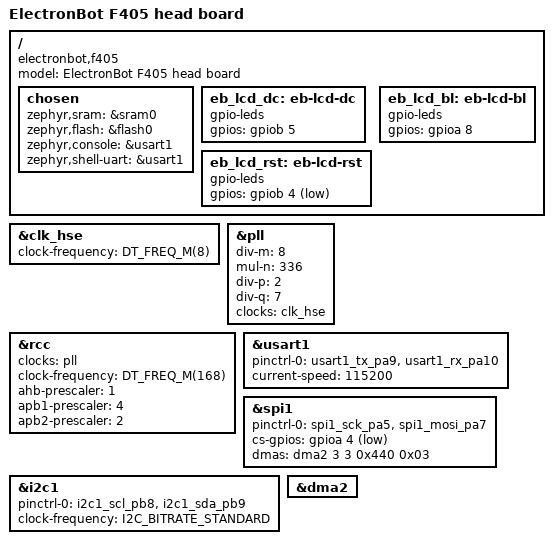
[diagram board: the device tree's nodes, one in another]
/*
 * ElectronBot head board - STM32F405RGT6.
 *
 * Pin assignments below follow the original design (SPI1 for the GC9A01 LCD,
 * I2C1 SCL=PB8 / SDA=PB9 for the servo bus). CONFIRM against 1.Hardware before
 * relying on them - marked with TODO where the schematic is the source of truth.
 */
/dts-v1/;
#include <st/f4/stm32f405Xg.dtsi>
#include <st/f4/stm32f405rgtx-pinctrl.dtsi>
#include <zephyr/dt-bindings/gpio/gpio.h>

/ {
	model = "ElectronBot F405 head board";
	compatible = "electronbot,f405";

	chosen {
		zephyr,sram = &sram0;
		zephyr,flash = &flash0;
		zephyr,console = &usart1;
		zephyr,shell-uart = &usart1;
	};

	/* LCD control GPIOs (DC / RST / backlight). TODO: confirm pins. */
	eb_lcd_dc: eb-lcd-dc {
		compatible = "gpio-leds";
		gpios = <&gpiob 5 GPIO_ACTIVE_HIGH>;
	};
	eb_lcd_rst: eb-lcd-rst {
		compatible = "gpio-leds";
		gpios = <&gpiob 4 GPIO_ACTIVE_LOW>;
	};
	eb_lcd_bl: eb-lcd-bl {
		compatible = "gpio-leds";
		gpios = <&gpioa 8 GPIO_ACTIVE_HIGH>;
	};
};

/* High-speed external crystal (8 MHz on the original board). */
&clk_hse {
	clock-frequency = <DT_FREQ_M(8)>;
	status = "okay";
};

&pll {
	div-m = <8>;
	mul-n = <336>;
	div-p = <2>;
	div-q = <7>;
	clocks = <&clk_hse>;
	status = "okay";
};

&rcc {
	clocks = <&pll>;
	clock-frequency = <DT_FREQ_M(168)>;
	ahb-prescaler = <1>;
	apb1-prescaler = <4>;
	apb2-prescaler = <2>;
};

&usart1 {
	pinctrl-0 = <&usart1_tx_pa9 &usart1_rx_pa10>;
	pinctrl-names = "default";
	current-speed = <115200>;
	status = "okay";
};

/* GC9A01 LCD bus. */
eb_lcd_spi: &spi1 {
	pinctrl-0 = <&spi1_sck_pa5 &spi1_mosi_pa7>;
	pinctrl-names = "default";
	cs-gpios = <&gpioa 4 GPIO_ACTIVE_LOW>;   /* TODO: confirm CS pin */
	status = "okay";
	/* DMA wiring for stripe streaming. TODO: confirm DMA stream/channel. */
	dmas = <&dma2 3 3 0x440 0x03>;
	dma-names = "tx";
};

/* Servo bus (I2C master). SCL=PB8, SDA=PB9 per the original firmware. */
eb_servo_i2c: &i2c1 {
	pinctrl-0 = <&i2c1_scl_pb8 &i2c1_sda_pb9>;
	pinctrl-names = "default";
	clock-frequency = <I2C_BITRATE_STANDARD>;
	status = "okay";
};

&dma2 {
	status = "okay";
};
